# IOC register map
Vendor: Texas Instruments
Peripheral module from a debugger description file (folder CC26x4).
Registers are 32-bit, access per field, reset 0xC000 unless marked. A register's access mark holds for its fields unless they carry their own. Offsets are as the file gives them; lines under a group give offsets from that group; [hi:lo] are bit positions; {n}, {i} and the like mark numbered series; 'fields as' and 'values as' point back to an identical list; <NAME> marks a mode.

## IOC — IO Controller (IOC) - configures all the DIOs and resides in the MCU domain. Note: Performing a write operation that includes IOC.IOCFGn.PORT_ID, may cause glitches on the IO. This can happen even if the write operation does not actually change the PORT_ID field (i.e. the write operation writes the same value as it already held) . This happens because the write operation triggers activities in the IOC that may, in some cases, cause glitches. To avoid glitches refrain from writing to this field other than when needed to actually change the PORT_ID value. Note that it is possible to write to parts of the IOCFGn register without writing to PORT_ID by using byte oriented writes to the parts of the register that do not contain PORT_ID
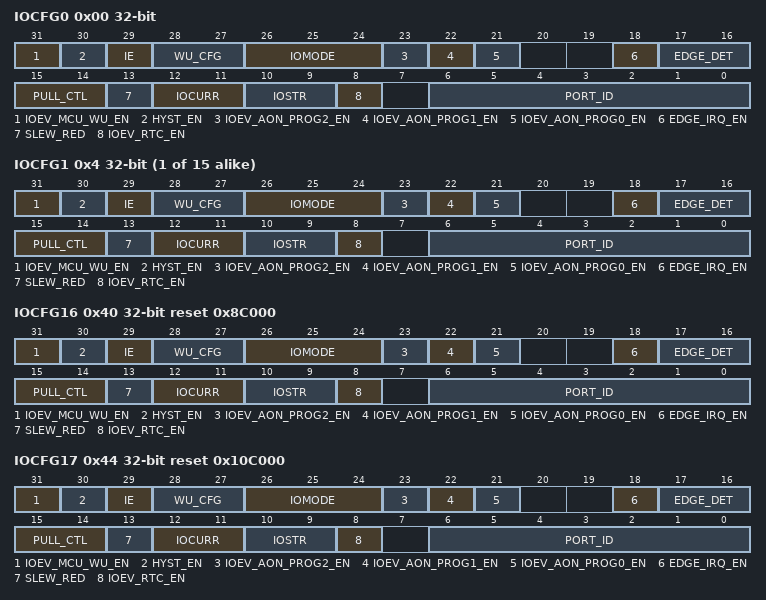
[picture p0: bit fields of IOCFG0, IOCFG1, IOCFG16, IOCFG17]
0x00 IOCFG0 — Configuration of DIO0
  [31] IOEV_MCU_WU_EN rw — Event asserted by this IO when edge detection is enabled 0: Input edge detection does not assert MCU_WU event 1: Input edge detection asserts MCU_WU event
  [30] HYST_EN rw — 0: Input hysteresis disable 1: Input hysteresis enable
  [29] IE rw — 0: Input disabled 1: Input enabled Note: If IO is configured for AUX PORT_ID = 0x08, the enable will be ignored.
  [28:27] WU_CFG rw — If DIO is configured GPIO or non-AON peripheral signals, PORT_ID 0x00 or >0x08: 00: No wake-up 01: No wake-up 10: Wakes up from shutdown if this pad is going low. 11: Wakes up from shutdown if this pad is going high. If IO is configured for AON peripheral signals or AUX PORT_ID 0x01-0x08, this register only sets wakeup enable or not. 00, 01: Wakeup disabled 10, 11: Wakeup enabled Polarity is controlled from AON registers. Note:When the MSB is set, the IOC will deactivate the output enable for the DIO.
  [26:24] IOMODE rw — IO Mode Not applicable for IO configured for AON periph. signals and AUX PORT_ID 0x01-0x08 AUX has its own open_source/drain configuration. 0x2: Reserved. Undefined behavior. 0x3: Reserved. Undefined behavior.
    7=OPENSRC_INV (Open Source Inverted input/output); 6=OPENSRC (Open Source Normal input / outut); 5=OPENDR_INV (Open Drain Inverted input / output); 4=OPENDR (Open Drain, Normal input / output); 1=INV (Inverted input / ouput); 0=NORMAL (Normal input / output)
  [23] IOEV_AON_PROG2_EN rw — Event asserted by this IO when edge detection is enabled 0: Input edge detection does not assert AON_PROG2 event 1: Input edge detection asserts AON_PROG2 event
  [22] IOEV_AON_PROG1_EN rw — Event asserted by this IO when edge detection is enabled 0: Input edge detection does not assert AON_PROG1 event 1: Input edge detection asserts AON_PROG1 event
  [21] IOEV_AON_PROG0_EN rw — Event asserted by this IO when edge detection is enabled 0: Input edge detection does not assert AON_PROG0 event 1: Input edge detection asserts AON_PROG0 event
  [18] EDGE_IRQ_EN rw — 0: No interrupt generation 1: Enable interrupt generation for this IO (Only effective if EDGE_DET is enabled)
  [17:16] EDGE_DET rw — Enable generation of edge detection events on this IO
    3=BOTH (Positive and negative edge detection); 2=POS (Positive edge detection); 1=NEG (Negative edge detection); 0=NONE (No edge detection)
  [15:14] PULL_CTL rw — Pull control
    3=DIS (No pull); 2=UP (Pull up); 1=DWN (Pull down)
  [13] SLEW_RED rw — 0: Normal slew rate 1: Enables reduced slew rate in output driver.
  [12:11] IOCURR rw — Selects IO current mode of this IO.
    2=4_8MA (Extended-Current (EC) mode: Min 8 mA for double drive strength IOs (min 4 mA for normal IOs) when IOSTR is set to AUTO); 1=4MA (High-Current (HC) mode: Min 4 mA when IOSTR is set to AUTO); 0=2MA (Low-Current (LC) mode: Min 2 mA when IOSTR is set to AUTO)
  [10:9] IOSTR rw — Select source for drive strength control of this IO. This setting controls the drive strength of the Low-Current (LC) mode. Higher drive strength can be selected in IOCURR
    3=MAX (Maximum drive strength, controlled by AON_IOC:IOSTRMAX (min 2 mA @1.8V with default values)); 2=MED (Medium drive strength, controlled by AON_IOC:IOSTRMED (min 2 mA @2.5V with default values)); 1=MIN (Minimum drive strength, controlled by AON_IOC:IOSTRMIN (min 2 mA @3.3V with default values)); 0=AUTO (Automatic drive strength, controlled by AON BATMON based on battery voltage. (min 2 mA @VDDS))
  [8] IOEV_RTC_EN rw — Event asserted by this IO when edge detection is enabled 0: Input edge detection does not assert RTC event 1: Input edge detection asserts RTC event
  [6:0] PORT_ID rw — Selects usage for DIO0 Note: This field should not be written other than the times when PORT_ID value is specifically required to change.
    74=I2C1_MSSCL (I2C1 Clock); 73=I2C1_MSSDA (I2C1 Data); 72=UART3_RTS; 71=UART3_CTS; 70=UART3_TX; 69=UART3_RX; 68=UART2_RTS; 67=UART2_CTS; 66=UART2_TX; 65=UART2_RX; 64=SPI3_CLK; 63=SPI3_CS; 62=SPI3_TX; 61=SPI3_RX; 60=SPI2_CLK; 59=SPI2_CS; 58=SPI2_TX; 57=SPI2_RX; 56=RFC_SMI_CL_IN (RF Core SMI Command Link In); 55=RFC_SMI_CL_OUT (RF Core SMI Command Link Out); 54=RFC_SMI_DL_IN (RF Core SMI Data Link In); 53=RFC_SMI_DL_OUT (RF Core SMI Data Link Out); 52=RFC_GPI1 (RF Core Data In 1); 51=RFC_GPI0 (RF Core Data In 0); {v}=RFC_GPO{v-47} (RF Core Data Out {v-47}) (v=47..50); 46=RFC_TRC (RF Core Trace); 41=I2S_MCLK; 40=I2S_BCLK; 39=I2S_WCLK; 38=I2S_AD1 (I2S Data 1); 37=I2S_AD0 (I2S Data 0); 36=SPI1_CLK; 35=SPI1_CS; 34=SPI1_TX; 33=SPI1_RX; 32=CPU_SWV; {v}=PORT_EVENT{v-23} (PORT EVENT {v-23} Can be used as a general purpose IO event by selecting it through registers in the EVENT module, for example EVENT:GPT0ACAPTSEL.EV, EVENT:UDMACH14BSEL.EV, and so on) (v=23..30); 22=UART1_RTS; 21=UART1_CTS; 20=UART1_TX; 19=UART1_RX; 18=UART0_RTS; 17=UART0_CTS; 16=UART0_TX; 15=UART0_RX; 14=I2C0_MSSCL (I2C0 Clock); 13=I2C0_MSSDA (I2C0 Data); 12=SPI0_CLK; 11=SPI0_CS; 10=SPI0_TX; 9=SPI0_RX; 8=AUX_IO; 7=AON_CLK32K (AON 32 KHz clock (SCLK_LF)); 0=GPIO (General Purpose IO)
{0x0+4i} IOCFG{i} (i=1..15) — Configuration of DIO{i}
  [31] IOEV_MCU_WU_EN rw — Event asserted by this IO when edge detection is enabled 0: Input edge detection does not assert MCU_WU event 1: Input edge detection asserts MCU_WU event
  [30] HYST_EN rw — 0: Input hysteresis disable 1: Input hysteresis enable
  [29] IE rw — 0: Input disabled 1: Input enabled Note: If IO is configured for AUX PORT_ID = 0x08, the enable will be ignored.
  [28:27] WU_CFG rw — If DIO is configured GPIO or non-AON peripheral signals, PORT_ID 0x00 or >0x08: 00: No wake-up 01: No wake-up 10: Wakes up from shutdown if this pad is going low. 11: Wakes up from shutdown if this pad is going high. If IO is configured for AON peripheral signals or AUX PORT_ID 0x01-0x08, this register only sets wakeup enable or not. 00, 01: Wakeup disabled 10, 11: Wakeup enabled Polarity is controlled from AON registers. Note:When the MSB is set, the IOC will deactivate the output enable for the DIO.
  [26:24] IOMODE rw — IO Mode Not applicable for IO configured for AON periph. signals and AUX PORT_ID 0x01-0x08 AUX has its own open_source/drain configuration. 0x2: Reserved. Undefined behavior. 0x3: Reserved. Undefined behavior.
    7=OPENSRC_INV (Open Source Inverted input / output); 6=OPENSRC (Open Source Normal input / output); 5=OPENDR_INV (Open Drain Inverted input / output); 4=OPENDR (Open Drain, Normal input / output); 1=INV (Inverted input / ouput); 0=NORMAL (Normal input / output)
  [23] IOEV_AON_PROG2_EN rw — Event asserted by this IO when edge detection is enabled 0: Input edge detection does not assert AON_PROG2 event 1: Input edge detection asserts AON_PROG2 event
  [22] IOEV_AON_PROG1_EN rw — Event asserted by this IO when edge detection is enabled 0: Input edge detection does not assert AON_PROG1 event 1: Input edge detection asserts AON_PROG1 event
  [21] IOEV_AON_PROG0_EN rw — Event asserted by this IO when edge detection is enabled 0: Input edge detection does not assert AON_PROG0 event 1: Input edge detection asserts AON_PROG0 event
  [18] EDGE_IRQ_EN rw — 0: No interrupt generation 1: Enable interrupt generation for this IO (Only effective if EDGE_DET is enabled)
  [17:16] EDGE_DET rw — Enable generation of edge detection events on this IO
    values as IOCFG0.EDGE_DET
  [15:14] PULL_CTL rw — Pull control
    3=DIS (No pull); 2=UP (Pull up); 1=DWN (Pull down)
  [13] SLEW_RED rw — 0: Normal slew rate 1: Enables reduced slew rate in output driver.
  [12:11] IOCURR rw — Selects IO current mode of this IO.
    values as IOCFG0.IOCURR
  [10:9] IOSTR rw — Select source for drive strength control of this IO. This setting controls the drive strength of the Low-Current (LC) mode. Higher drive strength can be selected in IOCURR
    values as IOCFG0.IOSTR
  [8] IOEV_RTC_EN rw — Event asserted by this IO when edge detection is enabled 0: Input edge detection does not assert RTC event 1: Input edge detection asserts RTC event
  [6:0] PORT_ID rw — Selects usage for DIO{i} Note: This field should not be written other than the times when PORT_ID value is specifically required to change.
    values as IOCFG0.PORT_ID
0x40 IOCFG16 reset 0x8C000 — Configuration of DIO16
  [31] IOEV_MCU_WU_EN rw — Event asserted by this IO when edge detection is enabled 0: Input edge detection does not assert MCU_WU event 1: Input edge detection asserts MCU_WU event
  [30] HYST_EN rw — 0: Input hysteresis disable 1: Input hysteresis enable
  [29] IE rw — 0: Input disabled 1: Input enabled Note: If IO is configured for AUX PORT_ID = 0x08, the enable will be ignored.
  [28:27] WU_CFG rw — If DIO is configured GPIO or non-AON peripheral signals, PORT_ID 0x00 or >0x08: 00: No wake-up 01: No wake-up 10: Wakes up from shutdown if this pad is going low. 11: Wakes up from shutdown if this pad is going high. If IO is configured for AON peripheral signals or AUX PORT_ID 0x01-0x08, this register only sets wakeup enable or not. 00, 01: Wakeup disabled 10, 11: Wakeup enabled Polarity is controlled from AON registers. Note:When the MSB is set, the IOC will deactivate the output enable for the DIO.
  [26:24] IOMODE rw — IO Mode Not applicable for IO configured for AON periph. signals and AUX PORT_ID 0x01-0x08 AUX has its own open_source/drain configuration. 0x2: Reserved. Undefined behavior. 0x3: Reserved. Undefined behavior.
    values as IOCFG1.IOMODE
  [23] IOEV_AON_PROG2_EN rw — Event asserted by this IO when edge detection is enabled 0: Input edge detection does not assert AON_PROG2 event 1: Input edge detection asserts AON_PROG2 event
  [22] IOEV_AON_PROG1_EN rw — Event asserted by this IO when edge detection is enabled 0: Input edge detection does not assert AON_PROG1 event 1: Input edge detection asserts AON_PROG1 event
  [21] IOEV_AON_PROG0_EN rw — Event asserted by this IO when edge detection is enabled 0: Input edge detection does not assert AON_PROG0 event 1: Input edge detection asserts AON_PROG0 event
  [18] EDGE_IRQ_EN rw — 0: No interrupt generation 1: Enable interrupt generation for this IO (Only effective if EDGE_DET is enabled)
  [17:16] EDGE_DET rw — Enable generation of edge detection events on this IO
    values as IOCFG0.EDGE_DET
  [15:14] PULL_CTL rw — Pull control
    3=DIS (No pull); 2=UP (Pull up); 1=DWN (Pull down)
  [13] SLEW_RED rw — 0: Normal slew rate 1: Enables reduced slew rate in output driver.
  [12:11] IOCURR rw — Selects IO current mode of this IO.
    values as IOCFG0.IOCURR
  [10:9] IOSTR rw — Select source for drive strength control of this IO. This setting controls the drive strength of the Low-Current (LC) mode. Higher drive strength can be selected in IOCURR
    values as IOCFG0.IOSTR
  [8] IOEV_RTC_EN rw — Event asserted by this IO when edge detection is enabled 0: Input edge detection does not assert RTC event 1: Input edge detection asserts RTC event
  [6:0] PORT_ID rw — Selects usage for DIO16 Note: This field should not be written other than the times when PORT_ID value is specifically required to change.
    values as IOCFG0.PORT_ID
0x44 IOCFG17 reset 0x10C000 — Configuration of DIO17
  [31] IOEV_MCU_WU_EN rw — Event asserted by this IO when edge detection is enabled 0: Input edge detection does not assert MCU_WU event 1: Input edge detection asserts MCU_WU event
  [30] HYST_EN rw — 0: Input hysteresis disable 1: Input hysteresis enable
  [29] IE rw — 0: Input disabled 1: Input enabled Note: If IO is configured for AUX PORT_ID = 0x08, the enable will be ignored.
  [28:27] WU_CFG rw — If DIO is configured GPIO or non-AON peripheral signals, PORT_ID 0x00 or >0x08: 00: No wake-up 01: No wake-up 10: Wakes up from shutdown if this pad is going low. 11: Wakes up from shutdown if this pad is going high. If IO is configured for AON peripheral signals or AUX PORT_ID 0x01-0x08, this register only sets wakeup enable or not. 00, 01: Wakeup disabled 10, 11: Wakeup enabled Polarity is controlled from AON registers. Note:When the MSB is set, the IOC will deactivate the output enable for the DIO.
  [26:24] IOMODE rw — IO Mode Not applicable for IO configured for AON periph. signals and AUX PORT_ID 0x01-0x08 AUX has its own open_source/drain configuration. 0x2: Reserved. Undefined behavior. 0x3: Reserved. Undefined behavior.
    values as IOCFG1.IOMODE
  [23] IOEV_AON_PROG2_EN rw — Event asserted by this IO when edge detection is enabled 0: Input edge detection does not assert AON_PROG2 event 1: Input edge detection asserts AON_PROG2 event
  [22] IOEV_AON_PROG1_EN rw — Event asserted by this IO when edge detection is enabled 0: Input edge detection does not assert AON_PROG1 event 1: Input edge detection asserts AON_PROG1 event
  [21] IOEV_AON_PROG0_EN rw — Event asserted by this IO when edge detection is enabled 0: Input edge detection does not assert AON_PROG0 event 1: Input edge detection asserts AON_PROG0 event
  [18] EDGE_IRQ_EN rw — 0: No interrupt generation 1: Enable interrupt generation for this IO (Only effective if EDGE_DET is enabled)
  [17:16] EDGE_DET rw — Enable generation of edge detection events on this IO
    values as IOCFG0.EDGE_DET
  [15:14] PULL_CTL rw — Pull control
    3=DIS (No pull); 2=UP (Pull up); 1=DWN (Pull down)
  [13] SLEW_RED rw — 0: Normal slew rate 1: Enables reduced slew rate in output driver.
  [12:11] IOCURR rw — Selects IO current mode of this IO.
    values as IOCFG0.IOCURR
  [10:9] IOSTR rw — Select source for drive strength control of this IO. This setting controls the drive strength of the Low-Current (LC) mode. Higher drive strength can be selected in IOCURR
    values as IOCFG0.IOSTR
  [8] IOEV_RTC_EN rw — Event asserted by this IO when edge detection is enabled 0: Input edge detection does not assert RTC event 1: Input edge detection asserts RTC event
  [6:0] PORT_ID rw — Selects usage for DIO17 Note: This field should not be written other than the times when PORT_ID value is specifically required to change.
    values as IOCFG0.PORT_ID
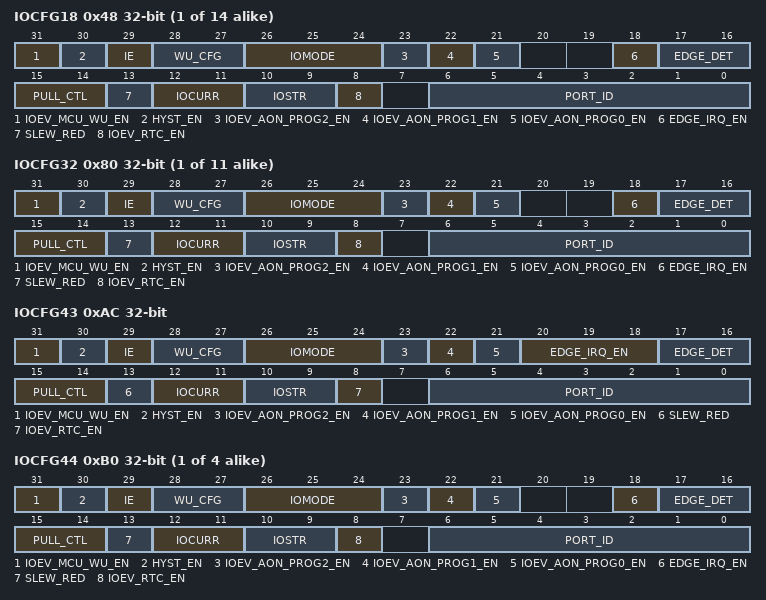
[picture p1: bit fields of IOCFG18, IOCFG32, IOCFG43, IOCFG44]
{0x0+4i} IOCFG{i} (i=18..31) — Configuration of DIO{i}
  fields as IOCFG1
{0x0+4i} IOCFG{i} (i=32..42) — Configuration of DIO{i}
  [31] IOEV_MCU_WU_EN rw — Event asserted by this IO when edge detection is enabled 0: Input edge detection does not assert MCU_WU event 1: Input edge detection asserts MCU_WU event
  [30] HYST_EN rw — 0: Input hysteresis disable 1: Input hysteresis enable
  [29] IE rw — 0: Input disabled 1: Input enabled Note: If IO is configured for AUX PORT_ID = 0x08, the enable will be ignored.
  [28:27] WU_CFG rw — If DIO is configured GPIO or non-AON peripheral signals, PORT_ID 0x00 or >0x08: 00: No wake-up 01: No wake-up 10: Wakes up from shutdown if this pad is going low. 11: Wakes up from shutdown if this pad is going high. If IO is configured for AON peripheral signals or AUX PORT_ID 0x01-0x08, this register only sets wakeup enable or not. 00, 01: Wakeup disabled 10, 11: Wakeup enabled Polarity is controlled from AON registers. Note:When the MSB is set, the IOC will deactivate the output enable for the DIO.
  [26:24] IOMODE rw — IO Mode Not applicable for IO configured for AON periph. signals and AUX PORT_ID 0x01-0x08 AUX has its own open_source/drain configuration. 0x2: Reserved. Undefined behavior. 0x3: Reserved. Undefined behavior.
    values as IOCFG1.IOMODE
  [23] IOEV_AON_PROG2_EN rw — Event asserted by this IO when edge detection is enabled 0: Input edge detection does not assert AON_PROG2 event 1: Input edge detection asserts AON_PROG2 event
  [22] IOEV_AON_PROG1_EN rw — Event asserted by this IO when edge detection is enabled 0: Input edge detection does not assert AON_PROG1 event 1: Input edge detection asserts AON_PROG1 event
  [21] IOEV_AON_PROG0_EN rw — Event asserted by this IO when edge detection is enabled 0: Input edge detection does not assert AON_PROG0 event 1: Input edge detection asserts AON_PROG0 event
  [18] EDGE_IRQ_EN rw — 0: No interrupt generation 1: Enable interrupt generation for this IO (Only effective if EDGE_DET is enabled)
  [17:16] EDGE_DET rw — Enable generation of edge detection events on this IO
    values as IOCFG0.EDGE_DET
  [15:14] PULL_CTL rw — Pull control
    3=DIS (No pull); 2=UP (Pull up); 1=DWN (Pull down)
  [13] SLEW_RED rw — 0: Normal slew rate 1: Enables reduced slew rate in output driver.
  [12:11] IOCURR rw — Selects IO current mode of this IO.
    values as IOCFG0.IOCURR
  [10:9] IOSTR rw — Select source for drive strength control of this IO. This setting controls the drive strength of the Low-Current (LC) mode. Higher drive strength can be selected in IOCURR
    values as IOCFG0.IOSTR
  [8] IOEV_RTC_EN rw — Event asserted by this IO when edge detection is enabled 0: Input edge detection does not assert RTC event 1: Input edge detection asserts RTC event
  [6:0] PORT_ID rw — Selects usage for DIO{i} Note: This field should not be written other than the times when PORT_ID value is specifically required to change.
    74=I2C1_MSSCL (I2C1 Clock); 73=I2C1_MSSDA (I2C1 Data); 72=UART3_RTS; 71=UART3_CTS; 70=UART3_TX; 69=UART3_RX; 68=UART2_RTS; 67=UART2_CTS; 66=UART2_TX; 65=UART2_RX; 64=SPI3_CLK; 63=SPI3_CS; 62=SPI3_TX; 61=SPI3_RX; 60=SPI2_CLK; 59=SPI2_CS; 58=SPI2_TX; 57=SPI2_RX; 56=RFC_SMI_CL_IN (RF Core SMI Command Link In); 55=RFC_SMI_CL_OUT (RF Core SMI Command Link Out); 54=RFC_SMI_DL_IN (RF Core SMI Data Link In); 53=RFC_SMI_DL_OUT (RF Core SMI Data Link Out); 52=RFC_GPI1 (RF Core Data In 1); 51=RFC_GPI0 (RF Core Data In 0); {v}=RFC_GPO{v-47} (RF Core Data Out {v-47}) (v=47..50); 46=RFC_TRC (RF Core Trace); 41=I2S_MCLK; 40=I2S_BCLK; 39=I2S_WCLK; 38=I2S_AD1 (I2S Data 1); 37=I2S_AD0 (I2S Data 0); 36=SPI1_CLK; 35=SPI1_CS; 34=SPI1_TX; 33=SPI1_RX; 32=CPU_SWV; {v}=PORT_EVENT{v-23} (PORT EVENT {v-23} Can be used as a general purpose IO event by selecting it through registers in the EVENT module, for example EVENT:GPT0ACAPTSEL.EV, EVENT:UDMACH14BSEL.EV, and so on) (v=23..30); 22=UART1_RTS; 21=UART1_CTS; 20=UART1_TX; 19=UART1_RX; 18=UART0_RTS; 17=UART0_CTS; 16=UART0_TX; 15=UART0_RX; 14=I2C0_MSSCL (I2C0 Clock); 13=I2C0_MSSDA (I2C0 Data); 12=SPI0_CLK; 11=SPI0_CS; 10=SPI0_TX; 9=SPI0_RX; 7=AON_CLK32K (AON 32 KHz clock (SCLK_LF)); 0=GPIO (General Purpose IO)
0xAC IOCFG43 — Configuration of DIO43
  [31] IOEV_MCU_WU_EN rw — Event asserted by this IO when edge detection is enabled 0: Input edge detection does not assert MCU_WU event 1: Input edge detection asserts MCU_WU event
  [30] HYST_EN rw — 0: Input hysteresis disable 1: Input hysteresis enable
  [29] IE rw — 0: Input disabled 1: Input enabled Note: If IO is configured for AUX PORT_ID = 0x08, the enable will be ignored.
  [28:27] WU_CFG rw — If DIO is configured GPIO or non-AON peripheral signals, PORT_ID 0x00 or >0x08: 00: No wake-up 01: No wake-up 10: Wakes up from shutdown if this pad is going low. 11: Wakes up from shutdown if this pad is going high. If IO is configured for AON peripheral signals or AUX PORT_ID 0x01-0x08, this register only sets wakeup enable or not. 00, 01: Wakeup disabled 10, 11: Wakeup enabled Polarity is controlled from AON registers. Note:When the MSB is set, the IOC will deactivate the output enable for the DIO.
  [26:24] IOMODE rw — IO Mode Not applicable for IO configured for AON periph. signals and AUX PORT_ID 0x01-0x08 AUX has its own open_source/drain configuration. 0x2: Reserved. Undefined behavior. 0x3: Reserved. Undefined behavior.
    values as IOCFG1.IOMODE
  [23] IOEV_AON_PROG2_EN rw — Event asserted by this IO when edge detection is enabled 0: Input edge detection does not assert AON_PROG2 event 1: Input edge detection asserts AON_PROG2 event
  [22] IOEV_AON_PROG1_EN rw — Event asserted by this IO when edge detection is enabled 0: Input edge detection does not assert AON_PROG1 event 1: Input edge detection asserts AON_PROG1 event
  [21] IOEV_AON_PROG0_EN rw — Event asserted by this IO when edge detection is enabled 0: Input edge detection does not assert AON_PROG0 event 1: Input edge detection asserts AON_PROG0 event
  [20:18] EDGE_IRQ_EN rw — Software should not rely on the value of a reserved. Writing any other value than the reset value may result in undefined behavior.
  [17:16] EDGE_DET rw — Enable generation of edge detection events on this IO
    values as IOCFG0.EDGE_DET
  [15:14] PULL_CTL rw — Pull control
    3=DIS (No pull); 2=UP (Pull up); 1=DWN (Pull down)
  [13] SLEW_RED rw — 0: Normal slew rate 1: Enables reduced slew rate in output driver.
  [12:11] IOCURR rw — Selects IO current mode of this IO.
    values as IOCFG0.IOCURR
  [10:9] IOSTR rw — Select source for drive strength control of this IO. This setting controls the drive strength of the Low-Current (LC) mode. Higher drive strength can be selected in IOCURR
    values as IOCFG0.IOSTR
  [8] IOEV_RTC_EN rw — Event asserted by this IO when edge detection is enabled 0: Input edge detection does not assert RTC event 1: Input edge detection asserts RTC event
  [6:0] PORT_ID rw — Selects usage for DIO43 Note: This field should not be written other than the times when PORT_ID value is specifically required to change.
    values as IOCFG32.PORT_ID
{0x0+4i} IOCFG{i} (i=44..47) — Configuration of DIO{i}
  fields as IOCFG32
